# CY8C5888LTI_LP097 register map
File version: 0.1
Registers are 8-bit, read-write, no defined reset value unless marked. A register's access mark holds for its fields unless they carry their own. Offsets are from the block's base; [hi:lo] are bit positions; {n}, {i} and the like mark numbered series; 'fields as' and 'values as' point back to an identical list.

## CupSensor_Opamp_1
Base 0x00000000
0x400043A4 PM_ACT_CFG4 — Active Power Mode Configuration Register 4
  [3:0] EN_OPAMP — Enables subsystems during active power mode
    0=Blk_0 (Enables analog linear output buffer for Opamp block 0); 2=Blk_1 (Enables analog linear output buffer for Opamp block 1); 4=Blk_2 (Enables analog linear output buffer for Opamp block 2); 8=Blk_3 (Enables analog linear output buffer for Opamp block 3)
0x400043B4 PM_STBY_CFG4 — Standby Power Mode Configuration Register 4
  [3:0] EN_OPAMP — Enables subsystems during standby power mode
    values as PM_ACT_CFG4.EN_OPAMP
0x40004626 OPAMP__TR0 — Analog Output Buffer Trim Register 0
  [4:0] offset_trim — Offset Trim: 420uV typical step size; +/- 6.8mV offset trimmable range
0x40004627 OPAMP__TR1 — Analog Output Buffer Trim Register 1
0x4000585E OPAMP__CR — Analog Output Buffer Configuration Register
  [1:0] pwr_mode — Power Mode
    0=Default_Fast (Default Power mode Fast); 1=Slow (Power Mode Slow); 2=Medium (Power Mode Medium); 3=Fast (Power Mode Fast)
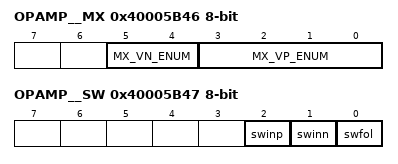
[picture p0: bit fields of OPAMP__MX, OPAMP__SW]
0x40005B46 OPAMP__MX — Analog Buffer Input Selection Register
  [5:4] MX_VN_ENUM — MUX select VN (Negative terminal input)
    0=OPAMP0_MX_VN_DEFAULT (Default - Not Connected (NC)); 1=OPAMP0_MX_VN_AG4 (MUX Selection AGL(4)); 2=OPAMP0_MX_VN_AG6 (MUX Selection AGL(6)); 3=OPAMP0_MX_VN_0x3 (Reserved (NC))
  [3:0] MX_VP_ENUM — MUX select VP (Positive terminal input)
    0=OPAMP0_MX_VP_DEFAULT (Default - Not Connected (NC)); {v}=OPAMP0_MX_VP_AG{v+3} (MUX Selection AGL({v+3})) (v=1..4); {v}=OPAMP0_MX_VP_ABUS{v-5} (MUX Selection ABUSL({v-5})) (v=5..8); 9=OPAMP0_MX_VP_VREF (MUX Selection: OPAMP Voltage Reference); {v}=OPAMP0_MX_VP_H_{0x0+v} (Reserved (NC)) (v=10..15)
0x40005B47 OPAMP__SW — Analog Buffer Routing Switch Register
  [2] swinp — Switch Enable Positive Input
  [1] swinn — Switch Enable Negative Input
  [0] swfol — Switch Enable Follow

## CupSensor_Control_Reg_Led
Base 0x00000000
0x4000647B CupSensor_Control_Reg_Led_CONTROL_REG

## UART
Base 0x00000000
0x40006448 TX_UART_TX_DATA — TX Data Register
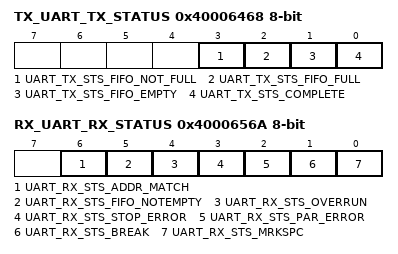
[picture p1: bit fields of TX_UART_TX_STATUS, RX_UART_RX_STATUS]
0x40006468 TX_UART_TX_STATUS — TX status register
  [3] UART_TX_STS_FIFO_NOT_FULL ro, [2] UART_TX_STS_FIFO_FULL ro, [1] UART_TX_STS_FIFO_EMPTY ro, [0] UART_TX_STS_COMPLETE ro
0x4000652A RX_UART_RX_ADDRESS1 — RX Address1 Register
0x4000653A RX_UART_RX_ADDRESS2 — RX Address2 Register
0x4000654A RX_UART_RX_DATA — RX Data Register
0x4000656A RX_UART_RX_STATUS — RX status register
  [6] UART_RX_STS_ADDR_MATCH ro, [5] UART_RX_STS_FIFO_NOTEMPTY ro, [4] UART_RX_STS_OVERRUN ro, [3] UART_RX_STS_STOP_ERROR ro, [2] UART_RX_STS_PAR_ERROR ro, [1] UART_RX_STS_BREAK ro, [0] UART_RX_STS_MRKSPC ro

## I2C
Base 0x00000000
0x4000640F I2C_DATA
  [7:0] data — Read received data or write data to transmit. These bits are held zero if I2C_CFG.en_mstr and I2C_CFG.en_slave are both zero.
0x4000642F I2C_ADDR — I2C Slave Adddress Register
  [6:0] slave_address — These seven bits hold the slave's own device address.
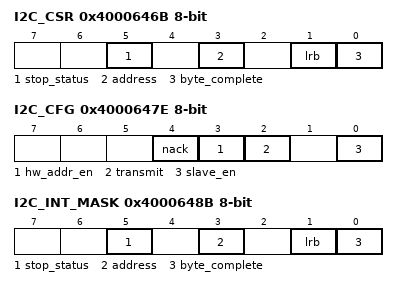
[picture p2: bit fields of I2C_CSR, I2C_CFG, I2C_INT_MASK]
0x4000646B I2C_CSR — I2C Status Register
  [5] stop_status ro — If set, indicates a Stop condition was detected on the bus.
  [3] address ro — Address detection. If set, indicates that an address byte was sent.
  [1] lrb ro — Last Received Bit. Indicates the state of the last received bit, which is the ACK/NAK received for the last byte transmitted. Cleared = ACK and set = NAK.
  [0] byte_complete ro — Transmit or receive status since the last read of this register. In Transmit mode this bit indicates that eight bits of data plus ACK/NAK have been transmitted since the last read. In Receive mode this bit indicates that eight bits of data have been received since the last read of this register.
0x4000647E I2C_CFG — I2C Configuration Register
  [4] nack — If set, used to NAK the last byte received. This bit must be cleared by firmware between bytes.
  [3] hw_addr_en — If set, used to enable the device to respond any device addresses it receives rather than just the single address provided in I2C_ADDRESS.
  [2] transmit — Used to set the mode to transmit or receive data. This bit must be cleared by firmware between bytes. Set = transmit and cleared = receive.
  [0] slave_en — Set to 1 to enable the slave functionality.
0x4000648B I2C_INT_MASK — I2C Interrupt Enable Mask
  [5] stop_status — Enables interrupt from the corresponding bit in status register.
  [3] address — Enables interrupt from the corresponding bit in status register.
  [1] lrb — Enables interrupt from the corresponding bit in status register.
  [0] byte_complete — Enables interrupt from the corresponding bit in status register.

## Timer
Base 0x00000000
0x40006406 Timer_COUNTER 16-bit — UDB.A0 - Current Down Counter Value
0x40006426 Timer_PERIOD 16-bit — UDB.D0 - Assigned Period
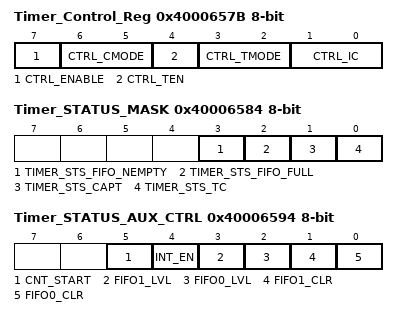
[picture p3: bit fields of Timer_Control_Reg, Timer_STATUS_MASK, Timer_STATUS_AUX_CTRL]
0x4000657B Timer_Control_Reg — UDB Control Register - Assigned Control Register Value
  [7] CTRL_ENABLE — Enable the Timer
  [6:5] CTRL_CMODE — Capture Mode
  [4] CTRL_TEN — Trigger Enable Bit
  [3:2] CTRL_TMODE — Trigger Mode
  [1:0] CTRL_IC — Interrupt Count
0x40006584 Timer_STATUS_MASK — UDB Status bits Interrupt Mask Enable Register
  [3] TIMER_STS_FIFO_NEMPTY ro — FIFO Empty status
  [2] TIMER_STS_FIFO_FULL ro — FIFO Full Status
  [1] TIMER_STS_CAPT ro — Enables the Interrupt on Capture
  [0] TIMER_STS_TC ro — Enables the Interrupt on TC
0x40006594 Timer_STATUS_AUX_CTRL — UDB Auxilliary Control Register
  [5] CNT_START — FIFO0 clear
    0=E_CNT_START0 (Disable counter); 1=E_CNT_START1 (Enable counter)
  [4] INT_EN
    0=E_INT_EN0 (Interrupt disabled); 1=E_INT_EN1 (Interrupt enabled)
  [3] FIFO1_LVL — FIFO level
    0=E_FIFO_LVL_0 (FIFO LVL: input mode: FIFO not full; output mode: FIFO not empty); 1=E_FIFO_LVL_1 (FIFO LVL: input mode: FIFO at least 1/2 empty; output mode: FIFO at least 1/2 full)
  [2] FIFO0_LVL — FIFO level
    values as FIFO1_LVL
  [1] FIFO1_CLR — FIFO1 clear
    0=E_FIFO_CLR_0 (Normal FIFO operation); 1=E_FIFO_CLR_1 (Clear FIFO state)
  [0] FIFO0_CLR — FIFO0 clear
    values as FIFO1_CLR
